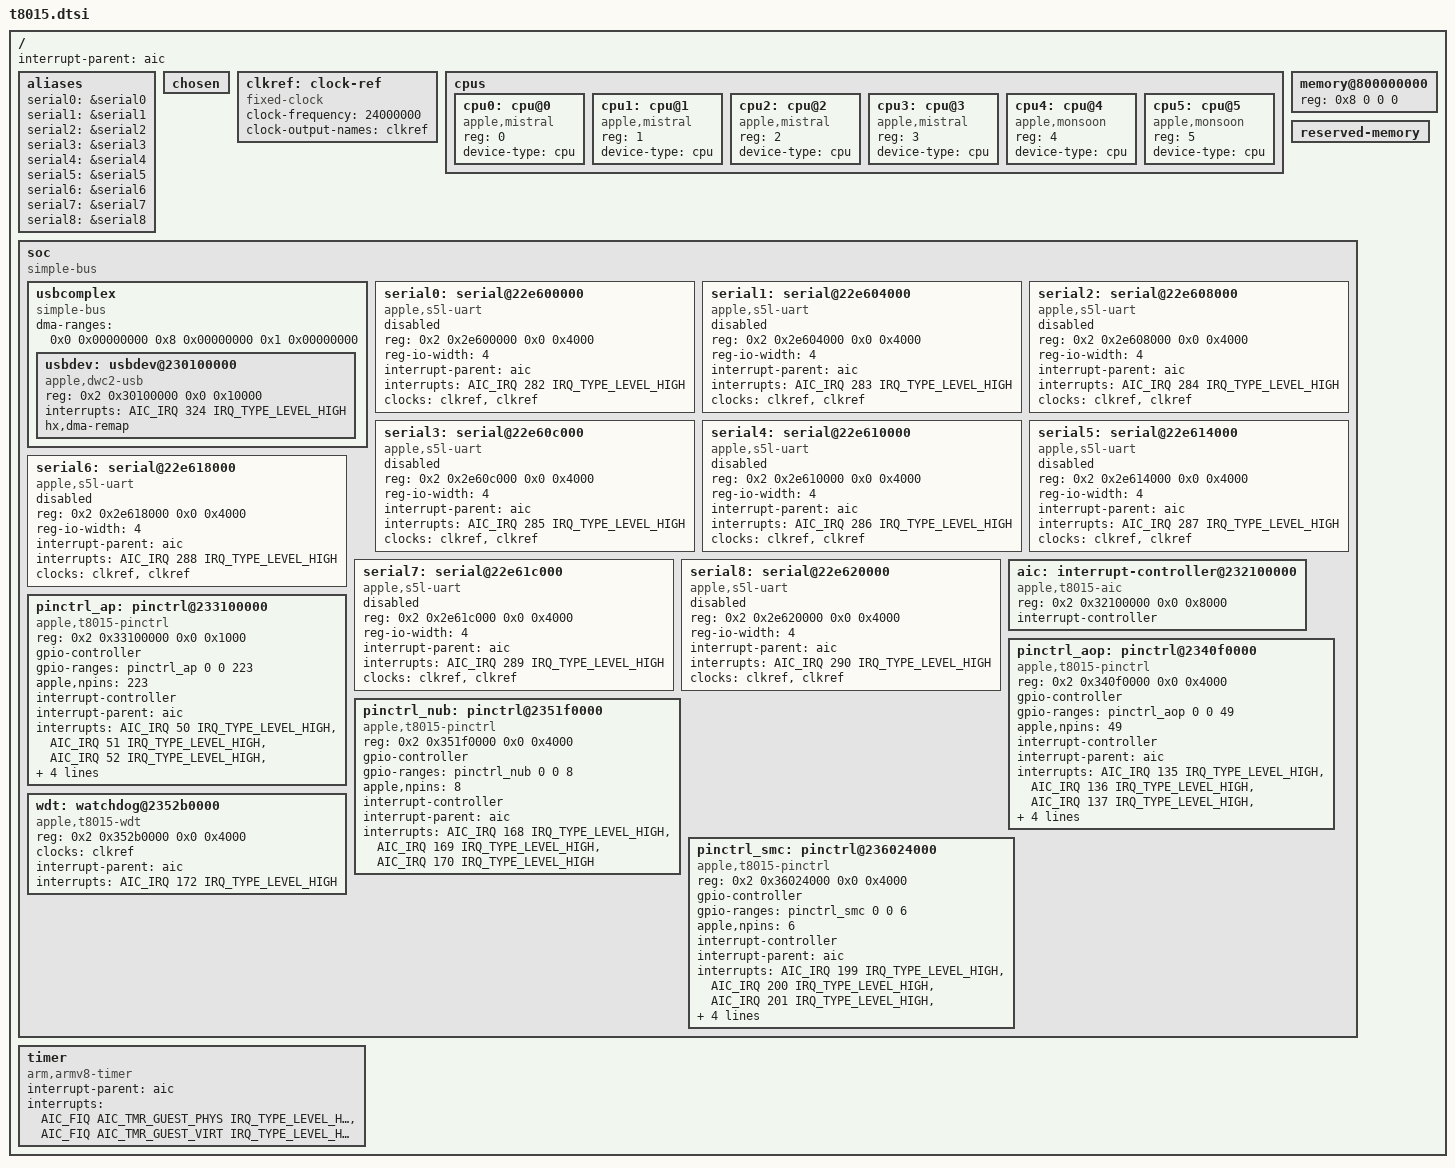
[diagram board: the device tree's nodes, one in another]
// SPDX-License-Identifier: GPL-2.0+ OR MIT
/*
 * Apple T8015 "A11" SoC
 *
 * Copyright (c) 2022, Konrad Dybcio <konrad.dybcio@somainline.org>
 * Based on Asahi Linux's M1 (t8103.dtsi) and Corellium's A10 efforts.
 */

#include <dt-bindings/gpio/gpio.h>
#include <dt-bindings/interrupt-controller/apple-aic.h>
#include <dt-bindings/interrupt-controller/irq.h>
#include <dt-bindings/pinctrl/apple.h>

/ {
	interrupt-parent = <&aic>;
	#address-cells = <2>;
	#size-cells = <2>;

	aliases {
		serial0 = &serial0;
		serial1 = &serial1;
		serial2 = &serial2;
		serial3 = &serial3;
		serial4 = &serial4;
		serial5 = &serial5;
		serial6 = &serial6;
		serial7 = &serial7;
		serial8 = &serial8;
	};

	chosen {
		#address-cells = <2>;
		#size-cells = <2>;
		ranges;
	};

	clkref: clock-ref {
		compatible = "fixed-clock";
		#clock-cells = <0>;
		clock-frequency = <24000000>;
		clock-output-names = "clkref";
	};

	cpus {
		#address-cells = <1>;
		#size-cells = <0>;

		cpu0: cpu@0 {
			compatible = "apple,mistral";
			reg = <0>;
			device-type = "cpu";
		};

		cpu1: cpu@1 {
			compatible = "apple,mistral";
			reg = <1>;
			device-type = "cpu";
		};

		cpu2: cpu@2 {
			compatible = "apple,mistral";
			reg = <2>;
			device-type = "cpu";
		};

		cpu3: cpu@3 {
			compatible = "apple,mistral";
			reg = <3>;
			device-type = "cpu";
		};

		cpu4: cpu@4 {
			compatible = "apple,monsoon";
			reg = <4>;
			device-type = "cpu";
		};

		cpu5: cpu@5 {
			compatible = "apple,monsoon";
			reg = <5>;
			device-type = "cpu";
		};
	};

	memory@800000000 {
		device_type = "memory";
		/* To be filled in by the bootloader (based on XNU BootArgs). */
		reg = <0x8 0 0 0>;
	};

	reserved-memory {
		#address-cells = <2>;
		#size-cells = <2>;
		ranges;

		/*
		 * The bootloader reserves a region for the (varying-address, depending
		 * on what FW your device runs AND model) framebuffer under this node.
		 */
	};

	soc {
		compatible = "simple-bus";
		#address-cells = <2>;
		#size-cells = <2>;
		ranges;

		usbcomplex {
			compatible = "simple-bus";
			#address-cells = <2>;
			#size-cells = <2>;
			dma-ranges = <0x0 0x00000000 0x8 0x00000000 0x1 0x00000000>;
			ranges;

			usbdev: usbdev@230100000 {
				compatible = "apple,dwc2-usb";
				reg = <0x2 0x30100000 0x0 0x10000>;
				interrupts = <AIC_IRQ 324 IRQ_TYPE_LEVEL_HIGH>;
				hx,dma-remap;
			};
		};

		serial0: serial@22e600000 {
			compatible = "apple,s5l-uart";
			reg = <0x2 0x2e600000 0x0 0x4000>;
			reg-io-width = <4>;
			interrupt-parent = <&aic>;
			interrupts = <AIC_IRQ 282 IRQ_TYPE_LEVEL_HIGH>;
			/* Use the bootloader-enabled clocks for now. */
			clocks = <&clkref>, <&clkref>;
			clock-names = "uart", "clk_uart_baud0";
			status = "disabled";
		};

		serial1: serial@22e604000 {
			compatible = "apple,s5l-uart";
			reg = <0x2 0x2e604000 0x0 0x4000>;
			reg-io-width = <4>;
			interrupt-parent = <&aic>;
			interrupts = <AIC_IRQ 283 IRQ_TYPE_LEVEL_HIGH>;
			/* Use the bootloader-enabled clocks for now. */
			clocks = <&clkref>, <&clkref>;
			clock-names = "uart", "clk_uart_baud0";
			status = "disabled";
		};

		serial2: serial@22e608000 {
			compatible = "apple,s5l-uart";
			reg = <0x2 0x2e608000 0x0 0x4000>;
			reg-io-width = <4>;
			interrupt-parent = <&aic>;
			interrupts = <AIC_IRQ 284 IRQ_TYPE_LEVEL_HIGH>;
			/* Use the bootloader-enabled clocks for now. */
			clocks = <&clkref>, <&clkref>;
			clock-names = "uart", "clk_uart_baud0";
			status = "disabled";
		};

		serial3: serial@22e60c000 {
			compatible = "apple,s5l-uart";
			reg = <0x2 0x2e60c000 0x0 0x4000>;
			reg-io-width = <4>;
			interrupt-parent = <&aic>;
			interrupts = <AIC_IRQ 285 IRQ_TYPE_LEVEL_HIGH>;
			/* Use the bootloader-enabled clocks for now. */
			clocks = <&clkref>, <&clkref>;
			clock-names = "uart", "clk_uart_baud0";
			status = "disabled";
		};

		serial4: serial@22e610000 {
			compatible = "apple,s5l-uart";
			reg = <0x2 0x2e610000 0x0 0x4000>;
			reg-io-width = <4>;
			interrupt-parent = <&aic>;
			interrupts = <AIC_IRQ 286 IRQ_TYPE_LEVEL_HIGH>;
			/* Use the bootloader-enabled clocks for now. */
			clocks = <&clkref>, <&clkref>;
			clock-names = "uart", "clk_uart_baud0";
			status = "disabled";
		};

		serial5: serial@22e614000 {
			compatible = "apple,s5l-uart";
			reg = <0x2 0x2e614000 0x0 0x4000>;
			reg-io-width = <4>;
			interrupt-parent = <&aic>;
			interrupts = <AIC_IRQ 287 IRQ_TYPE_LEVEL_HIGH>;
			/* Use the bootloader-enabled clocks for now. */
			clocks = <&clkref>, <&clkref>;
			clock-names = "uart", "clk_uart_baud0";
			status = "disabled";
		};

		serial6: serial@22e618000 {
			compatible = "apple,s5l-uart";
			reg = <0x2 0x2e618000 0x0 0x4000>;
			reg-io-width = <4>;
			interrupt-parent = <&aic>;
			interrupts = <AIC_IRQ 288 IRQ_TYPE_LEVEL_HIGH>;
			/* Use the bootloader-enabled clocks for now. */
			clocks = <&clkref>, <&clkref>;
			clock-names = "uart", "clk_uart_baud0";
			status = "disabled";
		};

		serial7: serial@22e61c000 {
			compatible = "apple,s5l-uart";
			reg = <0x2 0x2e61c000 0x0 0x4000>;
			reg-io-width = <4>;
			interrupt-parent = <&aic>;
			interrupts = <AIC_IRQ 289 IRQ_TYPE_LEVEL_HIGH>;
			/* Use the bootloader-enabled clocks for now. */
			clocks = <&clkref>, <&clkref>;
			clock-names = "uart", "clk_uart_baud0";
			status = "disabled";
		};

		serial8: serial@22e620000 {
			compatible = "apple,s5l-uart";
			reg = <0x2 0x2e620000 0x0 0x4000>;
			reg-io-width = <4>;
			interrupt-parent = <&aic>;
			interrupts = <AIC_IRQ 290 IRQ_TYPE_LEVEL_HIGH>;
			/* Use the bootloader-enabled clocks for now. */
			clocks = <&clkref>, <&clkref>;
			clock-names = "uart", "clk_uart_baud0";
			status = "disabled";
		};

		aic: interrupt-controller@232100000 {
			compatible = "apple,t8015-aic", "apple,aic";
			reg = <0x2 0x32100000 0x0 0x8000>;
			#interrupt-cells = <3>;
			interrupt-controller;
		};

		pinctrl_ap: pinctrl@233100000 {
			compatible = "apple,t8015-pinctrl", "apple,pinctrl";
			reg = <0x2 0x33100000 0x0 0x1000>;

			gpio-controller;
			#gpio-cells = <2>;
			gpio-ranges = <&pinctrl_ap 0 0 223>;
			apple,npins = <223>;

			interrupt-controller;
			#interrupt-cells = <2>;
			interrupt-parent = <&aic>;
			interrupts = <AIC_IRQ 50 IRQ_TYPE_LEVEL_HIGH>,
				     <AIC_IRQ 51 IRQ_TYPE_LEVEL_HIGH>,
				     <AIC_IRQ 52 IRQ_TYPE_LEVEL_HIGH>,
				     <AIC_IRQ 53 IRQ_TYPE_LEVEL_HIGH>,
				     <AIC_IRQ 54 IRQ_TYPE_LEVEL_HIGH>,
				     <AIC_IRQ 55 IRQ_TYPE_LEVEL_HIGH>,
				     <AIC_IRQ 56 IRQ_TYPE_LEVEL_HIGH>;
		};

		pinctrl_aop: pinctrl@2340f0000 {
			compatible = "apple,t8015-pinctrl", "apple,pinctrl";
			reg = <0x2 0x340f0000 0x0 0x4000>;

			gpio-controller;
			#gpio-cells = <2>;
			gpio-ranges = <&pinctrl_aop 0 0 49>;
			apple,npins = <49>;

			interrupt-controller;
			#interrupt-cells = <2>;
			interrupt-parent = <&aic>;
			interrupts = <AIC_IRQ 135 IRQ_TYPE_LEVEL_HIGH>,
				     <AIC_IRQ 136 IRQ_TYPE_LEVEL_HIGH>,
				     <AIC_IRQ 137 IRQ_TYPE_LEVEL_HIGH>,
				     <AIC_IRQ 138 IRQ_TYPE_LEVEL_HIGH>,
				     <AIC_IRQ 139 IRQ_TYPE_LEVEL_HIGH>,
				     <AIC_IRQ 140 IRQ_TYPE_LEVEL_HIGH>,
				     <AIC_IRQ 141 IRQ_TYPE_LEVEL_HIGH>;
		};

		pinctrl_nub: pinctrl@2351f0000 {
			compatible = "apple,t8015-pinctrl", "apple,pinctrl";
			reg = <0x2 0x351f0000 0x0 0x4000>;

			gpio-controller;
			#gpio-cells = <2>;
			gpio-ranges = <&pinctrl_nub 0 0 8>;
			apple,npins = <8>;

			interrupt-controller;
			#interrupt-cells = <2>;
			interrupt-parent = <&aic>;
			interrupts = <AIC_IRQ 168 IRQ_TYPE_LEVEL_HIGH>,
				     <AIC_IRQ 169 IRQ_TYPE_LEVEL_HIGH>,
				     <AIC_IRQ 170 IRQ_TYPE_LEVEL_HIGH>;
		};

		wdt: watchdog@2352b0000 {
			compatible = "apple,t8015-wdt", "apple,wdt";
			reg = <0x2 0x352b0000 0x0 0x4000>;
			clocks = <&clkref>;
			interrupt-parent = <&aic>;
			interrupts = <AIC_IRQ 172 IRQ_TYPE_LEVEL_HIGH>;
		};

		pinctrl_smc: pinctrl@236024000 {
			compatible = "apple,t8015-pinctrl", "apple,pinctrl";
			reg = <0x2 0x36024000 0x0 0x4000>;

			gpio-controller;
			#gpio-cells = <2>;
			gpio-ranges = <&pinctrl_smc 0 0 6>;
			apple,npins = <6>;

			interrupt-controller;
			#interrupt-cells = <2>;
			interrupt-parent = <&aic>;
			interrupts = <AIC_IRQ 199 IRQ_TYPE_LEVEL_HIGH>,
				     <AIC_IRQ 200 IRQ_TYPE_LEVEL_HIGH>,
				     <AIC_IRQ 201 IRQ_TYPE_LEVEL_HIGH>,
				     <AIC_IRQ 202 IRQ_TYPE_LEVEL_HIGH>,
				     <AIC_IRQ 203 IRQ_TYPE_LEVEL_HIGH>,
				     <AIC_IRQ 204 IRQ_TYPE_LEVEL_HIGH>,
				     <AIC_IRQ 205 IRQ_TYPE_LEVEL_HIGH>;
		};
	};

	timer {
		compatible = "arm,armv8-timer";
		interrupt-parent = <&aic>;
		interrupt-names = "phys", "virt";
		/* Note that A11 doesn't actually have a hypervisor (EL2 is not implemented). */
		interrupts = <AIC_FIQ AIC_TMR_GUEST_PHYS IRQ_TYPE_LEVEL_HIGH>,
			     <AIC_FIQ AIC_TMR_GUEST_VIRT IRQ_TYPE_LEVEL_HIGH>;
	};
};
